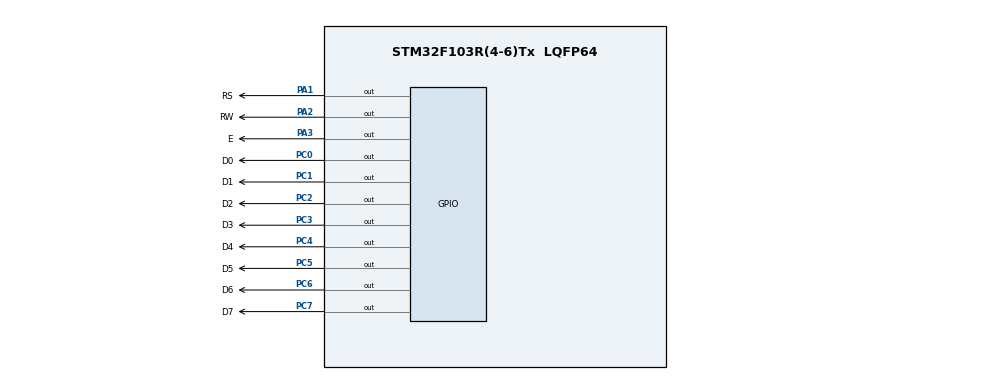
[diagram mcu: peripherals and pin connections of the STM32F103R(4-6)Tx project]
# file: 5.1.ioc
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Mcu.Family=STM32F1
Mcu.Name=STM32F103R(4-6)Tx
Mcu.Package=LQFP64
NVIC.PriorityGroup=NVIC_PRIORITYGROUP_4
PA1.GPIO_Label=RS
PA1.GPIO_ModeDefaultOutputPP=GPIO_MODE_OUTPUT_PP
PA1.GPIO_PuPd=GPIO_PULLUP
PA1.GPIO_Speed=GPIO_SPEED_FREQ_LOW
PA1.PinState=GPIO_PIN_SET
PA1.Signal=GPIO_Output
PA2.GPIO_Label=RW
PA2.GPIO_ModeDefaultOutputPP=GPIO_MODE_OUTPUT_PP
PA2.GPIO_PuPd=GPIO_PULLUP
PA2.GPIO_Speed=GPIO_SPEED_FREQ_LOW
PA2.PinState=GPIO_PIN_SET
PA2.Signal=GPIO_Output
PA3.GPIO_Label=E
PA3.GPIO_ModeDefaultOutputPP=GPIO_MODE_OUTPUT_PP
PA3.GPIO_PuPd=GPIO_PULLUP
PA3.GPIO_Speed=GPIO_SPEED_FREQ_LOW
PA3.PinState=GPIO_PIN_SET
PA3.Signal=GPIO_Output
PC0.GPIO_Label=D0
PC0.GPIO_ModeDefaultOutputPP=GPIO_MODE_OUTPUT_PP
PC0.GPIO_PuPd=GPIO_PULLUP
PC0.GPIO_Speed=GPIO_SPEED_FREQ_LOW
PC0.PinState=GPIO_PIN_SET
PC0.Signal=GPIO_Output
PC1.GPIO_Label=D1
PC1.GPIO_ModeDefaultOutputPP=GPIO_MODE_OUTPUT_PP
PC1.GPIO_PuPd=GPIO_PULLUP
PC1.GPIO_Speed=GPIO_SPEED_FREQ_LOW
PC1.PinState=GPIO_PIN_SET
PC1.Signal=GPIO_Output
PC2.GPIO_Label=D2
PC2.GPIO_ModeDefaultOutputPP=GPIO_MODE_OUTPUT_PP
PC2.GPIO_PuPd=GPIO_PULLUP
PC2.GPIO_Speed=GPIO_SPEED_FREQ_LOW
PC2.PinState=GPIO_PIN_SET
PC2.Signal=GPIO_Output
PC3.GPIO_Label=D3
PC3.GPIO_ModeDefaultOutputPP=GPIO_MODE_OUTPUT_PP
PC3.GPIO_PuPd=GPIO_PULLUP
PC3.GPIO_Speed=GPIO_SPEED_FREQ_LOW
PC3.PinState=GPIO_PIN_SET
PC3.Signal=GPIO_Output
PC4.GPIO_Label=D4
PC4.GPIO_ModeDefaultOutputPP=GPIO_MODE_OUTPUT_PP
PC4.GPIO_PuPd=GPIO_PULLUP
PC4.GPIO_Speed=GPIO_SPEED_FREQ_LOW
PC4.PinState=GPIO_PIN_SET
PC4.Signal=GPIO_Output
PC5.GPIO_Label=D5
PC5.GPIO_ModeDefaultOutputPP=GPIO_MODE_OUTPUT_PP
PC5.GPIO_PuPd=GPIO_PULLUP
PC5.GPIO_Speed=GPIO_SPEED_FREQ_LOW
PC5.PinState=GPIO_PIN_SET
PC5.Signal=GPIO_Output
PC6.GPIO_Label=D6
PC6.GPIO_ModeDefaultOutputPP=GPIO_MODE_OUTPUT_PP
PC6.GPIO_PuPd=GPIO_PULLUP
PC6.GPIO_Speed=GPIO_SPEED_FREQ_LOW
PC6.PinState=GPIO_PIN_SET
PC6.Signal=GPIO_Output
PC7.GPIO_Label=D7
PC7.GPIO_ModeDefaultOutputPP=GPIO_MODE_OUTPUT_PP
PC7.GPIO_PuPd=GPIO_PULLUP
PC7.GPIO_Speed=GPIO_SPEED_FREQ_LOW
PC7.PinState=GPIO_PIN_SET
PC7.Signal=GPIO_Output
ProjectManager.HeapSize=0x200
ProjectManager.StackSize=0x400
ProjectManager.TargetToolchain=STM32CubeIDE
RCC.APB1Freq_Value=8000000
RCC.APB2Freq_Value=8000000
VP_SYS_VS_ND.Mode=No_Debug
board=custom

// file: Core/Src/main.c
/* USER CODE BEGIN Header */
/**
  ******************************************************************************
  * @file           : main.c
  * @brief          : Main program body
  ******************************************************************************
  * @attention
  *
  * <h2><center>&copy; Copyright (c) 2020 STMicroelectronics.
  * All rights reserved.</center></h2>
  *
  * This software component is licensed by ST under BSD 3-Clause license,
  * the "License"; You may not use this file except in compliance with the
  * License. You may obtain a copy of the License at:
  *                        opensource.org/licenses/BSD-3-Clause
  *
  ******************************************************************************
  */
/* USER CODE END Header */

#include "main.h"

/* USER CODE BEGIN Includes */
#include "LCD1602.h"
/* USER CODE END Includes */

void SystemClock_Config(void);
static void MX_GPIO_Init(void);

int main(void)
{
  /* USER CODE BEGIN 1 */
	char str[]="Hello World!";
  /* USER CODE END 1 */

  /* MCU Configuration--------------------------------------------------------*/

  /* Reset of all peripherals, Initializes the Flash interface and the Systick. */
  HAL_Init();

  /* Configure the system clock */
  SystemClock_Config();

  /* Initialize all configured peripherals */
  MX_GPIO_Init();
  /* USER CODE BEGIN 2 */
  LCD_Init();
  LCD_ShowString(0,0,str);
  /* USER CODE END 2 */

  /* Infinite loop */
  while (1)
  {

  }
}

void SystemClock_Config(void)
{
  RCC_OscInitTypeDef RCC_OscInitStruct = {0};
  RCC_ClkInitTypeDef RCC_ClkInitStruct = {0};

  /** Initializes the CPU, AHB and APB busses clocks
  */
  RCC_OscInitStruct.OscillatorType = RCC_OSCILLATORTYPE_HSI;
  RCC_OscInitStruct.HSIState = RCC_HSI_ON;
  RCC_OscInitStruct.HSICalibrationValue = RCC_HSICALIBRATION_DEFAULT;
  RCC_OscInitStruct.PLL.PLLState = RCC_PLL_NONE;
  if (HAL_RCC_OscConfig(&RCC_OscInitStruct) != HAL_OK)
  {
    Error_Handler();
  }
  /** Initializes the CPU, AHB and APB busses clocks
  */
  RCC_ClkInitStruct.ClockType = RCC_CLOCKTYPE_HCLK|RCC_CLOCKTYPE_SYSCLK
                              |RCC_CLOCKTYPE_PCLK1|RCC_CLOCKTYPE_PCLK2;
  RCC_ClkInitStruct.SYSCLKSource = RCC_SYSCLKSOURCE_HSI;
  RCC_ClkInitStruct.AHBCLKDivider = RCC_SYSCLK_DIV1;
  RCC_ClkInitStruct.APB1CLKDivider = RCC_HCLK_DIV1;
  RCC_ClkInitStruct.APB2CLKDivider = RCC_HCLK_DIV1;

  if (HAL_RCC_ClockConfig(&RCC_ClkInitStruct, FLASH_LATENCY_0) != HAL_OK)
  {
    Error_Handler();
  }
}

static void MX_GPIO_Init(void)
{
  GPIO_InitTypeDef GPIO_InitStruct = {0};

  /* GPIO Ports Clock Enable */
  __HAL_RCC_GPIOC_CLK_ENABLE();
  __HAL_RCC_GPIOA_CLK_ENABLE();

  /*Configure GPIO pin Output Level */
  HAL_GPIO_WritePin(GPIOC, D0_Pin|D1_Pin|D2_Pin|D3_Pin
                          |D4_Pin|D5_Pin|D6_Pin|D7_Pin, GPIO_PIN_SET);

  /*Configure GPIO pin Output Level */
  HAL_GPIO_WritePin(GPIOA, RS_Pin|RW_Pin|E_Pin, GPIO_PIN_SET);

  /*Configure GPIO pins : D0_Pin D1_Pin D2_Pin D3_Pin
                           D4_Pin D5_Pin D6_Pin D7_Pin */
  GPIO_InitStruct.Pin = D0_Pin|D1_Pin|D2_Pin|D3_Pin
                          |D4_Pin|D5_Pin|D6_Pin|D7_Pin;
  GPIO_InitStruct.Mode = GPIO_MODE_OUTPUT_PP;
  GPIO_InitStruct.Pull = GPIO_PULLUP;
  GPIO_InitStruct.Speed = GPIO_SPEED_FREQ_LOW;
  HAL_GPIO_Init(GPIOC, &GPIO_InitStruct);

  /*Configure GPIO pins : RS_Pin RW_Pin E_Pin */
  GPIO_InitStruct.Pin = RS_Pin|RW_Pin|E_Pin;
  GPIO_InitStruct.Mode = GPIO_MODE_OUTPUT_PP;
  GPIO_InitStruct.Pull = GPIO_PULLUP;
  GPIO_InitStruct.Speed = GPIO_SPEED_FREQ_LOW;
  HAL_GPIO_Init(GPIOA, &GPIO_InitStruct);

}

void Error_Handler(void)
{
}

/************************ (C) COPYRIGHT STMicroelectronics *****END OF FILE****/
